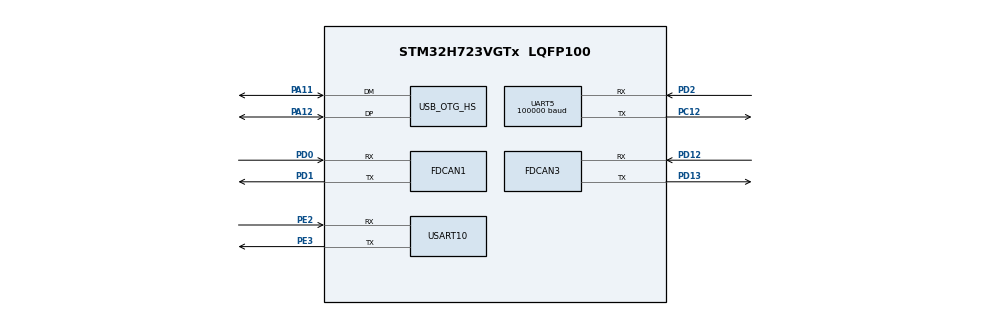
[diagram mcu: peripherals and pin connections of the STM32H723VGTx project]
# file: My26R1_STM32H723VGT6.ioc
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CORTEX_M7.default_mode_Activation=1
Dma.Request0=UART5_RX
Dma.Request1=USART10_RX
Dma.UART5_RX.0.Direction=DMA_PERIPH_TO_MEMORY
Dma.UART5_RX.0.EventEnable=DISABLE
Dma.UART5_RX.0.FIFOMode=DMA_FIFOMODE_DISABLE
Dma.UART5_RX.0.Instance=DMA1_Stream1
Dma.UART5_RX.0.MemDataAlignment=DMA_MDATAALIGN_BYTE
Dma.UART5_RX.0.MemInc=DMA_MINC_ENABLE
Dma.UART5_RX.0.Mode=DMA_CIRCULAR
Dma.UART5_RX.0.PeriphDataAlignment=DMA_PDATAALIGN_BYTE
Dma.UART5_RX.0.PeriphInc=DMA_PINC_DISABLE
Dma.UART5_RX.0.Polarity=HAL_DMAMUX_REQ_GEN_RISING
Dma.UART5_RX.0.Priority=DMA_PRIORITY_VERY_HIGH
Dma.UART5_RX.0.RequestNumber=1
Dma.UART5_RX.0.SignalID=NONE
Dma.UART5_RX.0.SyncEnable=DISABLE
Dma.UART5_RX.0.SyncPolarity=HAL_DMAMUX_SYNC_NO_EVENT
Dma.UART5_RX.0.SyncRequestNumber=1
Dma.UART5_RX.0.SyncSignalID=NONE
Dma.USART10_RX.1.Direction=DMA_PERIPH_TO_MEMORY
Dma.USART10_RX.1.EventEnable=DISABLE
Dma.USART10_RX.1.FIFOMode=DMA_FIFOMODE_DISABLE
Dma.USART10_RX.1.Instance=DMA1_Stream0
Dma.USART10_RX.1.MemDataAlignment=DMA_MDATAALIGN_BYTE
Dma.USART10_RX.1.MemInc=DMA_MINC_ENABLE
Dma.USART10_RX.1.Mode=DMA_CIRCULAR
Dma.USART10_RX.1.PeriphDataAlignment=DMA_PDATAALIGN_BYTE
Dma.USART10_RX.1.PeriphInc=DMA_PINC_DISABLE
Dma.USART10_RX.1.Polarity=HAL_DMAMUX_REQ_GEN_RISING
Dma.USART10_RX.1.Priority=DMA_PRIORITY_HIGH
Dma.USART10_RX.1.RequestNumber=1
Dma.USART10_RX.1.SignalID=NONE
Dma.USART10_RX.1.SyncEnable=DISABLE
Dma.USART10_RX.1.SyncPolarity=HAL_DMAMUX_SYNC_NO_EVENT
Dma.USART10_RX.1.SyncRequestNumber=1
Dma.USART10_RX.1.SyncSignalID=NONE
FDCAN1.CalculateBaudRateNominal=500000
FDCAN1.CalculateTimeBitNominal=2000
FDCAN1.CalculateTimeQuantumNominal=50.0
FDCAN1.DataPrescaler=3
FDCAN1.DataSyncJumpWidth=10
FDCAN1.DataTimeSeg1=29
FDCAN1.DataTimeSeg2=5
FDCAN1.ExtFiltersNbr=1
FDCAN1.NominalPrescaler=6
FDCAN1.NominalSyncJumpWidth=10
FDCAN1.NominalTimeSeg1=29
FDCAN1.NominalTimeSeg2=10
FDCAN1.RxFifo0ElmtsNbr=16
FDCAN1.RxFifo1ElmtsNbr=16
FDCAN1.TxFifoQueueElmtsNbr=8
FDCAN3.CalculateBaudRateNominal=1000000
FDCAN3.CalculateTimeBitNominal=1000
FDCAN3.CalculateTimeQuantumNominal=25.0
FDCAN3.DataPrescaler=3
FDCAN3.DataSyncJumpWidth=10
FDCAN3.DataTimeSeg1=29
FDCAN3.DataTimeSeg2=5
FDCAN3.ExtFiltersNbr=0
FDCAN3.MessageRAMOffset=1024
FDCAN3.NominalPrescaler=3
FDCAN3.NominalSyncJumpWidth=10
FDCAN3.NominalTimeSeg1=29
FDCAN3.NominalTimeSeg2=10
FDCAN3.RxFifo0ElmtsNbr=16
FDCAN3.RxFifo1ElmtsNbr=8
FDCAN3.StdFiltersNbr=1
FDCAN3.TxFifoQueueElmtsNbr=8
FREERTOS.Tasks01=defaultTask,24,128,StartDefaultTask,Default,NULL,Dynamic,NULL,NULL;chassis_task,24,1024,StartChassisTask,As weak,NULL,Dynamic,NULL,NULL
Mcu.Family=STM32H7
Mcu.Name=STM32H723VGTx
Mcu.Package=LQFP100
NVIC.DMA1_Stream0_IRQn=true\:5\:0\:false\:false\:true\:true\:false\:true\:true
NVIC.DMA1_Stream1_IRQn=true\:5\:0\:false\:false\:true\:false\:false\:true\:true
NVIC.FDCAN1_IT1_IRQn=true\:5\:0\:false\:false\:true\:true\:true\:true\:true
NVIC.FDCAN3_IT0_IRQn=true\:5\:0\:false\:false\:true\:true\:true\:true\:true
NVIC.OTG_HS_EP1_IN_IRQn=true\:5\:0\:false\:false\:true\:true\:true\:true\:true
NVIC.OTG_HS_EP1_OUT_IRQn=true\:5\:0\:false\:false\:true\:true\:true\:true\:true
NVIC.OTG_HS_IRQn=true\:5\:0\:false\:false\:true\:true\:false\:true\:true
NVIC.PriorityGroup=NVIC_PRIORITYGROUP_4
NVIC.TIM7_IRQn=true\:15\:0\:false\:false\:true\:false\:false\:true\:true
NVIC.TimeBase=TIM7_IRQn
NVIC.TimeBaseIP=TIM7
NVIC.UART5_IRQn=true\:5\:0\:false\:false\:true\:true\:true\:true\:true
NVIC.USART10_IRQn=true\:5\:0\:false\:false\:true\:true\:true\:true\:true
PA11.Mode=Device_Only_FS
PA11.Signal=USB_OTG_HS_DM
PA12.Mode=Device_Only_FS
PA12.Signal=USB_OTG_HS_DP
PC12.Mode=Asynchronous
PC12.Signal=UART5_TX
PD0.Mode=FDCAN_Activate
PD0.Signal=FDCAN1_RX
PD1.Mode=FDCAN_Activate
PD1.Signal=FDCAN1_TX
PD12.Mode=FDCAN_Activate
PD12.Signal=FDCAN3_RX
PD13.Mode=FDCAN_Activate
PD13.Signal=FDCAN3_TX
PD2.Mode=Asynchronous
PD2.Signal=UART5_RX
PE2.Mode=Asynchronous
PE2.Signal=USART10_RX
PE3.Mode=Asynchronous
PE3.Signal=USART10_TX
PH0-OSC_IN.Mode=HSE-External-Oscillator
PH0-OSC_IN.Signal=RCC_OSC_IN
PH1-OSC_OUT.Mode=HSE-External-Oscillator
PH1-OSC_OUT.Signal=RCC_OSC_OUT
ProjectManager.HeapSize=0x200
ProjectManager.StackSize=0x400
ProjectManager.TargetToolchain=MDK-ARM V5.32
RCC.ADCFreq_Value=48375000
RCC.APB1Freq_Value=120000000
RCC.APB2Freq_Value=120000000
RCC.APB3Freq_Value=120000000
RCC.APB4Freq_Value=120000000
RCC.CortexFreq_Value=480000000
RCC.D1PPRE=RCC_APB3_DIV2
RCC.D2PPRE1=RCC_APB1_DIV2
RCC.D2PPRE2=RCC_APB2_DIV2
RCC.D3PPRE=RCC_APB4_DIV2
RCC.DIVM1=2
RCC.DIVN1=40
RCC.DIVP1=1
RCC.DIVQ1=4
RCC.HCLKFreq_Value=240000000
RCC.HPRE=RCC_HCLK_DIV2
RCC.HSE_VALUE=24000000
RCC.PLLSourceVirtual=RCC_PLLSOURCE_HSE
RCC.SYSCLKFreq_VALUE=480000000
RCC.SYSCLKSource=RCC_SYSCLKSOURCE_PLLCLK
RCC.USBCLockSelection=RCC_USBCLKSOURCE_HSI48
RCC.USBFreq_Value=48000000
UART5.BaudRate=100000
UART5.Mode=MODE_RX
UART5.Parity=PARITY_EVEN
UART5.StopBits=UART_STOPBITS_2
UART5.WordLength=WORDLENGTH_9B
USART10.VirtualMode=VM_ASYNC
USB_DEVICE.CLASS_NAME_HS=CDC
USB_DEVICE.VirtualMode=Cdc
USB_DEVICE.VirtualModeHS=Cdc_HS
USB_OTG_HS.VirtualMode-Device_Only_FS=Device_Only_FS
VP_FREERTOS_VS_CMSIS_V2.Mode=CMSIS_V2
VP_MEMORYMAP_VS_MEMORYMAP.Mode=CurAppReg
VP_SYS_VS_tim7.Mode=TIM7
VP_USB_DEVICE_VS_USB_DEVICE_CDC_HS.Mode=CDC_HS
board=custom

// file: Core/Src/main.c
/* USER CODE BEGIN Header */
/**
  ******************************************************************************
  * @file           : main.c
  * @brief          : Main program body
  ******************************************************************************
  * @attention
  *
  * Copyright (c) 2026 STMicroelectronics.
  * All rights reserved.
  *
  * This software is licensed under terms that can be found in the LICENSE file
  * in the root directory of this software component.
  * If no LICENSE file comes with this software, it is provided AS-IS.
  *
  ******************************************************************************
  */
/* USER CODE END Header */
#include "main.h"
#include "FreeRTOS.h"
#include "cmsis_os2.h"
#include "dma.h"
#include "fdcan.h"
#include "usart.h"
#include "usb_device.h"
#include "gpio.h"

void SystemClock_Config(void);
static void MPU_Config(void);
void MX_FREERTOS_Init(void);

int main(void)
{

  /* MPU Configuration--------------------------------------------------------*/
  MPU_Config();

  /* MCU Configuration--------------------------------------------------------*/

  /* Reset of all peripherals, Initializes the Flash interface and the Systick. */
  HAL_Init();

  /* Configure the system clock */
  SystemClock_Config();

  /* Initialize all configured peripherals */
  MX_GPIO_Init();
  MX_DMA_Init();
  MX_FDCAN1_Init();
  MX_FDCAN3_Init();
  MX_UART5_Init();
  MX_USART10_UART_Init();
	//MX_USB_DEVICE_Init();

  /* Init scheduler */
  osKernelInitialize();  /* Call init function for freertos objects (in cmsis_os2.c) */
  MX_FREERTOS_Init();

  /* Start scheduler */
  osKernelStart();

  /* We should never get here as control is now taken by the scheduler */

  /* Infinite loop */
  while (1)
  {

  }
}

void SystemClock_Config(void)
{
  RCC_OscInitTypeDef RCC_OscInitStruct = {0};
  RCC_ClkInitTypeDef RCC_ClkInitStruct = {0};

  /** Supply configuration update enable
  */
  HAL_PWREx_ConfigSupply(PWR_LDO_SUPPLY);

  /** Configure the main internal regulator output voltage
  */
  __HAL_PWR_VOLTAGESCALING_CONFIG(PWR_REGULATOR_VOLTAGE_SCALE0);

  while(!__HAL_PWR_GET_FLAG(PWR_FLAG_VOSRDY)) {}

  /** Initializes the RCC Oscillators according to the specified parameters
  * in the RCC_OscInitTypeDef structure.
  */
  RCC_OscInitStruct.OscillatorType = RCC_OSCILLATORTYPE_HSI48|RCC_OSCILLATORTYPE_HSE;
  RCC_OscInitStruct.HSEState = RCC_HSE_ON;
  RCC_OscInitStruct.HSI48State = RCC_HSI48_ON;
  RCC_OscInitStruct.PLL.PLLState = RCC_PLL_ON;
  RCC_OscInitStruct.PLL.PLLSource = RCC_PLLSOURCE_HSE;
  RCC_OscInitStruct.PLL.PLLM = 2;
  RCC_OscInitStruct.PLL.PLLN = 40;
  RCC_OscInitStruct.PLL.PLLP = 1;
  RCC_OscInitStruct.PLL.PLLQ = 4;
  RCC_OscInitStruct.PLL.PLLR = 2;
  RCC_OscInitStruct.PLL.PLLRGE = RCC_PLL1VCIRANGE_3;
  RCC_OscInitStruct.PLL.PLLVCOSEL = RCC_PLL1VCOWIDE;
  RCC_OscInitStruct.PLL.PLLFRACN = 0;
  if (HAL_RCC_OscConfig(&RCC_OscInitStruct) != HAL_OK)
  {
    Error_Handler();
  }

  /** Initializes the CPU, AHB and APB buses clocks
  */
  RCC_ClkInitStruct.ClockType = RCC_CLOCKTYPE_HCLK|RCC_CLOCKTYPE_SYSCLK
                              |RCC_CLOCKTYPE_PCLK1|RCC_CLOCKTYPE_PCLK2
                              |RCC_CLOCKTYPE_D3PCLK1|RCC_CLOCKTYPE_D1PCLK1;
  RCC_ClkInitStruct.SYSCLKSource = RCC_SYSCLKSOURCE_PLLCLK;
  RCC_ClkInitStruct.SYSCLKDivider = RCC_SYSCLK_DIV1;
  RCC_ClkInitStruct.AHBCLKDivider = RCC_HCLK_DIV2;
  RCC_ClkInitStruct.APB3CLKDivider = RCC_APB3_DIV2;
  RCC_ClkInitStruct.APB1CLKDivider = RCC_APB1_DIV2;
  RCC_ClkInitStruct.APB2CLKDivider = RCC_APB2_DIV2;
  RCC_ClkInitStruct.APB4CLKDivider = RCC_APB4_DIV2;

  if (HAL_RCC_ClockConfig(&RCC_ClkInitStruct, FLASH_LATENCY_3) != HAL_OK)
  {
    Error_Handler();
  }
}

 /* MPU Configuration */

void MPU_Config(void)
{
  MPU_Region_InitTypeDef MPU_InitStruct = {0};

  /* Disables the MPU */
  HAL_MPU_Disable();

  /** Initializes and configures the Region and the memory to be protected
  */
  MPU_InitStruct.Enable = MPU_REGION_ENABLE;
  MPU_InitStruct.Number = MPU_REGION_NUMBER0;
  MPU_InitStruct.BaseAddress = 0x0;
  MPU_InitStruct.Size = MPU_REGION_SIZE_4GB;
  MPU_InitStruct.SubRegionDisable = 0x87;
  MPU_InitStruct.TypeExtField = MPU_TEX_LEVEL0;
  MPU_InitStruct.AccessPermission = MPU_REGION_NO_ACCESS;
  MPU_InitStruct.DisableExec = MPU_INSTRUCTION_ACCESS_DISABLE;
  MPU_InitStruct.IsShareable = MPU_ACCESS_SHAREABLE;
  MPU_InitStruct.IsCacheable = MPU_ACCESS_NOT_CACHEABLE;
  MPU_InitStruct.IsBufferable = MPU_ACCESS_NOT_BUFFERABLE;

  HAL_MPU_ConfigRegion(&MPU_InitStruct);
  /* Enables the MPU */
  HAL_MPU_Enable(MPU_PRIVILEGED_DEFAULT);

}

void HAL_TIM_PeriodElapsedCallback(TIM_HandleTypeDef *htim)
{
  if (htim->Instance == TIM7)
  {
    HAL_IncTick();
  }
}

void Error_Handler(void)
{
  __disable_irq();
  while (1)
  {
  }
}

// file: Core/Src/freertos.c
/* USER CODE BEGIN Header */
/**
  ******************************************************************************
  * File Name          : freertos.c
  * Description        : Code for freertos applications
  ******************************************************************************
  * @attention
  *
  * Copyright (c) 2026 STMicroelectronics.
  * All rights reserved.
  *
  * This software is licensed under terms that can be found in the LICENSE file
  * in the root directory of this software component.
  * If no LICENSE file comes with this software, it is provided AS-IS.
  *
  ******************************************************************************
  */
/* USER CODE END Header */

#include "FreeRTOS.h"
#include "task.h"
#include "main.h"
#include "FreeRTOS.h"
#include "cmsis_os2.h"

/* Definitions for defaultTask */
osThreadId_t defaultTaskHandle;
const osThreadAttr_t defaultTask_attributes = {
  .name = "defaultTask",
  .stack_size = 128 * 4,
  .priority = (osPriority_t) osPriorityNormal,
};
/* Definitions for chassis_task */
osThreadId_t chassis_taskHandle;
const osThreadAttr_t chassis_task_attributes = {
  .name = "chassis_task",
  .stack_size = 1024 * 4,
  .priority = (osPriority_t) osPriorityNormal,
};

void StartDefaultTask(void *argument);
void StartChassisTask(void *argument);

extern void MX_USB_DEVICE_Init(void);
void MX_FREERTOS_Init(void); /* (MISRA C 2004 rule 8.1) */

void MX_FREERTOS_Init(void) {

  /* Create the thread(s) */
  /* creation of defaultTask */
  defaultTaskHandle = osThreadNew(StartDefaultTask, NULL, &defaultTask_attributes);

  /* creation of chassis_task */
  chassis_taskHandle = osThreadNew(StartChassisTask, NULL, &chassis_task_attributes);

}

void StartDefaultTask(void *argument)
{
  /* init code for USB_DEVICE */
  /* USB is initialized by BspUsb::Init() in StartChassisTask. */
  /* USER CODE BEGIN StartDefaultTask */
  /* USB reception is serviced by the chassis loop; this task remains idle. */
  for(;;)
  {
    osDelay(1);
  }
  /* USER CODE END StartDefaultTask */
}

__weak void StartChassisTask(void *argument)
{
  for(;;)
  {
    osDelay(1);
  }
}
